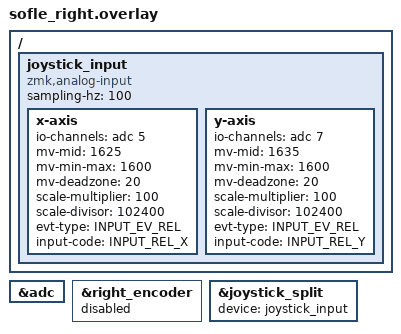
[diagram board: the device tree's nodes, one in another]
/* config/sofle_right.overlay */
#include "sofle.dtsi"
#include <dt-bindings/zmk/input_transform.h>
#include <dt-bindings/zmk/mouse.h>
#include <zephyr/dt-bindings/input/input-event-codes.h>

&adc {
    status = "okay";
};

&right_encoder {
    status = "disabled";
};

/ {
    joystick_input: joystick_input {
        compatible = "zmk,analog-input";
        status = "okay";
        sampling-hz = <100>;

        /* Define X Axis on Pin P0.29 (A5 / AIN5) - RIGHT SIDE */
        x-axis {
            io-channels = <&adc 5>;
            mv-mid = <1625>;
            mv-min-max = <1600>;
            mv-deadzone = <20>;
            scale-multiplier = <100>;
            scale-divisor = <102400>;
            evt-type = <INPUT_EV_REL>;
            input-code = <INPUT_REL_X>;
        };

        /* Define Y Axis on Pin P0.31 (A7 / AIN7) - RIGHT SIDE */
        y-axis {
            io-channels = <&adc 7>;
            mv-mid = <1635>;
            mv-min-max = <1600>;
            mv-deadzone = <20>;
            scale-multiplier = <100>;
            scale-divisor = <102400>;
            evt-type = <INPUT_EV_REL>;
            input-code = <INPUT_REL_Y>;
        };
    };

};

&joystick_split {
    device = <&joystick_input>;
};
